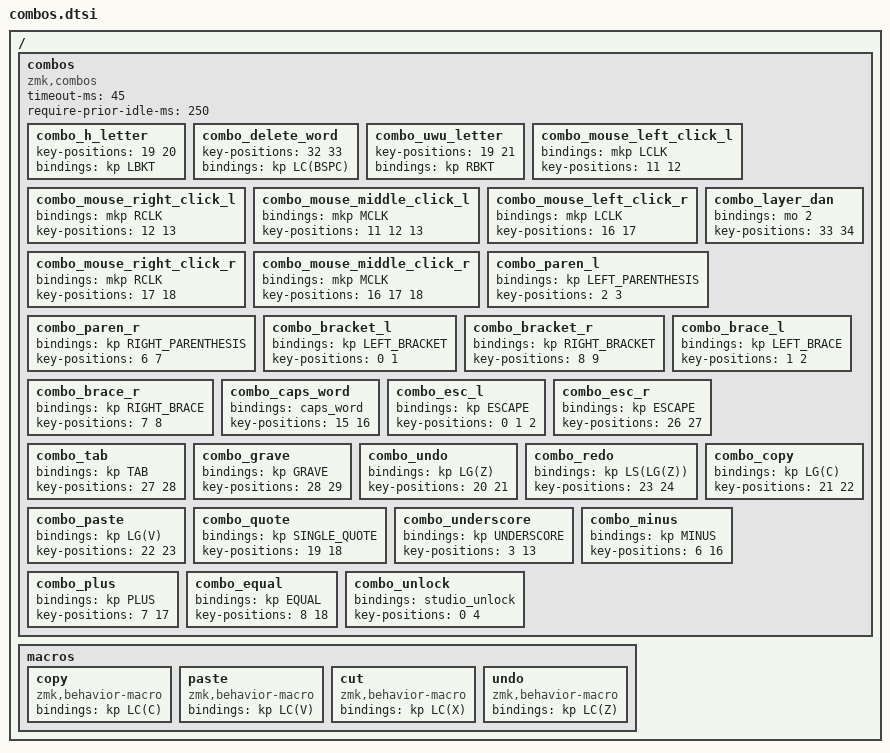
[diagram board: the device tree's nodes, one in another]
/ {
    combos {
        compatible = "zmk,combos";
         timeout-ms = <45>;
        require-prior-idle-ms = <250>;

         combo_h_letter {
           key-positions = <19 20>;
           bindings = <&kp LBKT>;
         };

         combo_delete_word {
           key-positions = <32 33>;
           bindings = <&kp LC(BSPC)>;
         };

         combo_uwu_letter {
           key-positions = <19 21>;
           bindings = <&kp RBKT>;
         };

        //INFO: Mouse clicks - left hand
        combo_mouse_left_click_l {
            bindings = <&mkp LCLK>;
            key-positions = <11 12>;
        };

        combo_mouse_right_click_l {
            bindings = <&mkp RCLK>;
            key-positions = <12 13>;
        };

        combo_mouse_middle_click_l {
            bindings = <&mkp MCLK>;
            key-positions = <11 12 13>;
        };

        //INFO: Mouse clicks - right hand
        combo_mouse_left_click_r {
            bindings = <&mkp LCLK>;
            key-positions = <16 17>;
        };

        combo_mouse_right_click_r {
            bindings = <&mkp RCLK>;
            key-positions = <17 18>;
        };

        combo_mouse_middle_click_r {
            bindings = <&mkp MCLK>;
            key-positions = <16 17 18>;
        };

        //INFO: Layer activation
        // combo_layer_scroll_l {
        //     bindings = <&mo 4>;
        //     key-positions = <21 22 23>;
        // };

        // combo_layer_snipe_l {
        //     bindings = <&mo 5>;
        //     key-positions = <20 21 22>;
        // };

        // combo_layer_scroll_r {
        //     bindings = <&mo 4>;
        //     key-positions = <26 27 28>;
        // };

        // combo_layer_snipe_r {
        //     bindings = <&mo 5>;
        //     key-positions = <27 28 29>;
        // };

        // combo_layer_auto {
        //     bindings = <&mo 5>;
        //     key-positions = <3 4>;
        // };

        combo_layer_dan {
            bindings = <&mo 2>;
            key-positions = <33 34>;
        };

        //INFO: Brackets and braces
        combo_paren_l {
            bindings = <&kp LEFT_PARENTHESIS>;
            key-positions = <2 3>;
        };

        combo_paren_r {
            bindings = <&kp RIGHT_PARENTHESIS>;
            key-positions = <6 7>;
        };

        combo_bracket_l {
            bindings = <&kp LEFT_BRACKET>;
            key-positions = <0 1>;
        };

        combo_bracket_r {
            bindings = <&kp RIGHT_BRACKET>;
            key-positions = <8 9>;
        };

        combo_brace_l {
            bindings = <&kp LEFT_BRACE>;
            key-positions = <1 2>;
        };

        combo_brace_r {
            bindings = <&kp RIGHT_BRACE>;
            key-positions = <7 8>;
        };

        //INFO: System commands
        combo_caps_word {
            bindings = <&caps_word>;
            key-positions = <15 16>;
        };

        combo_esc_l {
            bindings = <&kp ESCAPE>;
            key-positions = <0 1 2>;
        };

        combo_esc_r {
            bindings = <&kp ESCAPE>;
            key-positions = <26 27>;
        };

        combo_tab {
            bindings = <&kp TAB>;
            key-positions = <27 28>;
        };

        combo_grave {
            bindings = <&kp GRAVE>;
            key-positions = <28 29>;
        };

        //INFO: Edit commands
        combo_undo {
            bindings = <&kp LG(Z)>;
            key-positions = <20 21>;
        };

        combo_redo {
            bindings = <&kp LS(LG(Z))>;
            key-positions = <23 24>;
        };

        combo_copy {
            bindings = <&kp LG(C)>;
            key-positions = <21 22>;
        };

        combo_paste {
            bindings = <&kp LG(V)>;
            key-positions = <22 23>;
        };

        //INFO: Special characters
        combo_quote {
            bindings = <&kp SINGLE_QUOTE>;
            key-positions = <19 18>;
        };

        combo_underscore {
            bindings = <&kp UNDERSCORE>;
            key-positions = <3 13>;
        };

        combo_minus {
            bindings = <&kp MINUS>;
            key-positions = <6 16>;
        };

        combo_plus {
            bindings = <&kp PLUS>;
            key-positions = <7 17>;
        };

        combo_equal {
            bindings = <&kp EQUAL>;
            key-positions = <8 18>;
        };

        combo_unlock {
            bindings = <&studio_unlock>;
            key-positions = <0 4>;
        };

        // bt_clr {
        //     key-positions = <4 5>;
        //     bindings = <&bt BT_CLR>;
        //     layers = <NUMS>;
        // };
    };


        macros {
        copy: copy {
            compatible = "zmk,behavior-macro";
            #binding-cells = <0>;
            bindings = <&kp LC(C)>;
        };

        paste: paste {
            compatible = "zmk,behavior-macro";
            #binding-cells = <0>;
            bindings = <&kp LC(V)>;
        };

        cut: cut {
            compatible = "zmk,behavior-macro";
            #binding-cells = <0>;
            bindings = <&kp LC(X)>;
        };

        undo: undo {
            compatible = "zmk,behavior-macro";
            #binding-cells = <0>;
            bindings = <&kp LC(Z)>;
        };
    };
};

